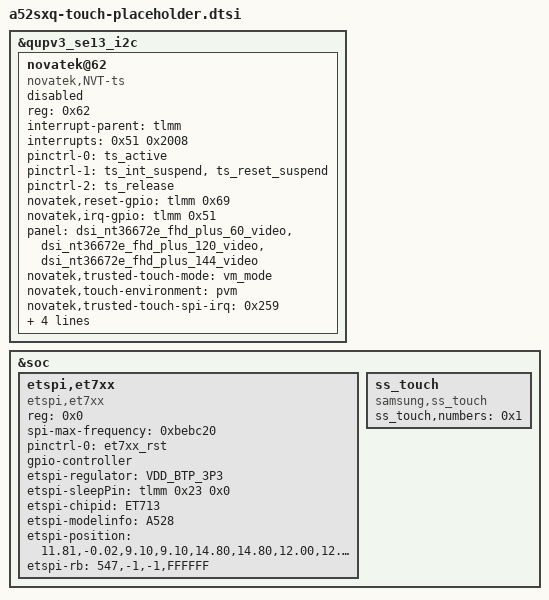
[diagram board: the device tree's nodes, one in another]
// SPDX-License-Identifier: GPL-2.0
/*
 * a52sxq board description for the Qualcomm 6.12 yupik base: touch (owned by agent 'touch': TODO-binding placeholder)
 * GENERATED by tools/gen.py from the phone's stock dtbo (5.4 bindings, values verbatim).
 * Do not edit: hand-written 6.12 changes live in a52sxq-bsp612-fixups.dtsi.
 */

&qupv3_se13_i2c {

	novatek@62 {
		compatible = "novatek,NVT-ts";
		reg = <0x62>;
		interrupt-parent = <&tlmm>;
		interrupts = <0x51 0x2008>;
		pinctrl-names = "pmx_ts_active", "pmx_ts_suspend", "pmx_ts_release";
		pinctrl-0 = <&ts_active>;
		pinctrl-1 = <&ts_int_suspend &ts_reset_suspend>;
		pinctrl-2 = <&ts_release>;
		novatek,reset-gpio = <&tlmm 0x69 0x0>;
		novatek,irq-gpio = <&tlmm 0x51 0x2008>;
		panel = <&dsi_nt36672e_fhd_plus_60_video &dsi_nt36672e_fhd_plus_120_video &dsi_nt36672e_fhd_plus_144_video>;
		novatek,trusted-touch-mode = "vm_mode";
		novatek,touch-environment = "pvm";
		novatek,trusted-touch-spi-irq = <0x259>;
		novatek,trusted-touch-io-bases = <0xf134000 0xf135000 0xf169000 0xf151000 0xa94000 0xa10000>;
		novatek,trusted-touch-io-sizes = <0x1000 0x1000 0x1000 0x1000 0x1000 0x4000>;
		status = "disabled";
	};
};

&soc {

	etspi,et7xx {
		compatible = "etspi,et7xx";
		reg = <0x0>;
		spi-max-frequency = <0xbebc20>;
		pinctrl-names = "default";
		pinctrl-0 = <&et7xx_rst>;
		gpio-controller;
		#gpio-cells = <0x2>;
		etspi-regulator = "VDD_BTP_3P3";
		etspi-sleepPin = <&tlmm 0x23 0x0>;
		etspi-chipid = "ET713";
		etspi-modelinfo = "A528";
		etspi-position = "11.81,-0.02,9.10,9.10,14.80,14.80,12.00,12.00,5.00";
		etspi-rb = "547,-1,-1,FFFFFF";
	};

	ss_touch {
		compatible = "samsung,ss_touch";
		ss_touch,numbers = <0x1>;
	};
};

